# xmc register map
Vendor: Texas Instruments
Peripheral module from a debugger description file (folder Keystone2).
Registers are 32-bit, read-write, no defined reset value unless marked. A register's access mark holds for its fields unless they carry their own. Offsets are as the file gives them; lines under a group give offsets from that group; [hi:lo] are bit positions; {n}, {i} and the like mark numbered series; 'fields as' and 'values as' point back to an identical list; <NAME> marks a mode.

## XMC
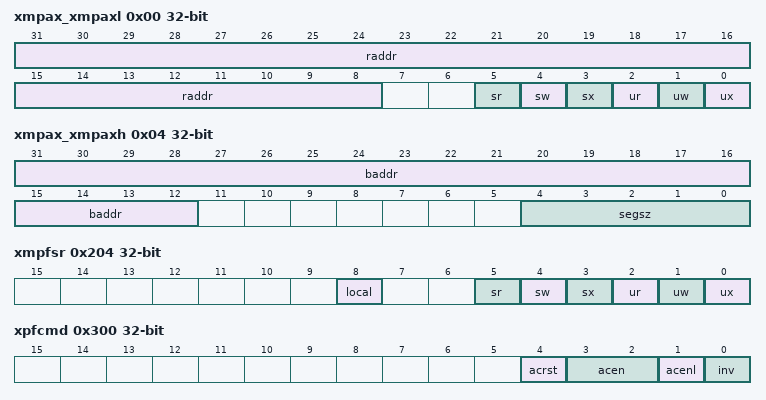
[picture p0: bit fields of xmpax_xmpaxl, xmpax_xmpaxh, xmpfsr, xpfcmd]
0x00 xmpax_xmpaxl — (1 of 16, stride 8)
  [31:8] raddr, [5] sr, [4] sw, [3] sx, [2] ur, [1] uw, [0] ux
0x04 xmpax_xmpaxh — (1 of 16, stride 8)
  [31:12] baddr, [4:0] segsz
0x200 xmpfar
  [31:0] faddr
0x204 xmpfsr
  [8] local, [5] sr, [4] sw, [3] sx, [2] ur, [1] uw, [0] ux
0x208 xmpfcr
  [0] mpfclr
0x280 mdmaarbx
  [18:16] pri
0x300 xpfcmd
  [4] acrst, [3:2] acen, [1] acenl, [0] inv
0x304 xpfacs
  [3:2] acen
0x310 xpfac0
  [19:0] sent
0x314 xpfac1
  [19:0] canceled
0x318 xpfac2
  [19:0] hit
0x31C xpfac3
  [19:0] miss
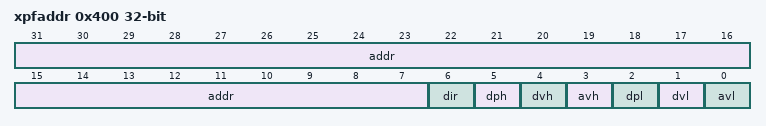
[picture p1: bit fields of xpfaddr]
0x400 xpfaddr — (1 of 8, stride 4)
  [31:7] addr, [6] dir, [5] dph, [4] dvh, [3] avh, [2] dpl, [1] dvl, [0] avl
